# R7FA6M4AF register map
Vendor: Renesas Electronics Corporation; Series: RA6; File version: 1.30.00
CPU: CM33 r0p4, little endian, MPU, FPU, VTOR, 4 interrupt priority bits, 96 interrupts
Registers are 8-bit, read-write, reset 0x0 unless marked. A register's access mark holds for its fields unless they carry their own. Offsets are from the block's base; [hi:lo] are bit positions.

## ETHERC0 — Ethernet Controller Channel 0
Base 0x40114100
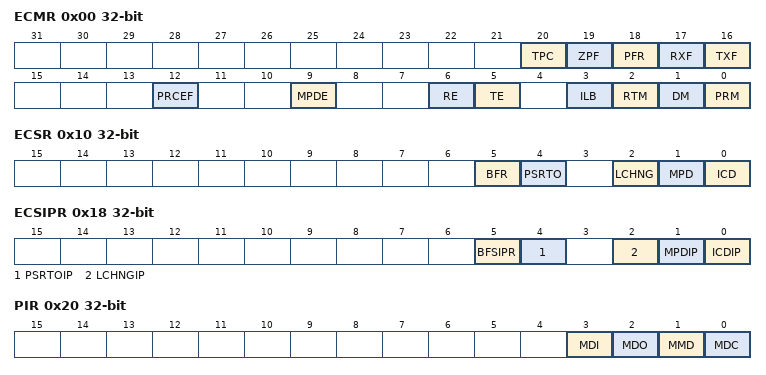
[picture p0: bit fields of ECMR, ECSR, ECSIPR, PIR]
0x00 ECMR 32-bit — ETHERC Mode Register
  [20] TPC — PAUSE Frame Transmit
  [19] ZPF — 0 Time PAUSE Frame Enable
  [18] PFR — PAUSE Frame Receive Mode
  [17] RXF — Receive Flow Control Operating Mode
  [16] TXF — Transmit Flow Control Operating Mode
  [12] PRCEF — CRC Error Frame Receive Mode
  [9] MPDE — Magic Packet Detection Enable
  [6] RE — Reception Enable
  [5] TE — Transmission Enable
  [3] ILB — Internal Loopback Mode
  [2] RTM — Bit Rate
  [1] DM — Duplex Mode
  [0] PRM — Promiscuous Mode
0x08 RFLR 32-bit — Receive Frame Maximum Length Register
  [11:0] RFL — Receive Frame Maximum Length
0x10 ECSR 32-bit — ETHERC Status Register
  [5] BFR — Continuous Broadcast Frame Reception Flag
  [4] PSRTO — PAUSE Frame Retransmit Over Flag
  [2] LCHNG — Link Signal Change Flag
  [1] MPD — Magic Packet Detect Flag
  [0] ICD — False Carrier Detect Flag
0x18 ECSIPR 32-bit — ETHERC Interrupt Enable Register
  [5] BFSIPR — Continuous Broadcast Frame Reception Interrupt Enable
  [4] PSRTOIP — PAUSE Frame Retransmit Over Interrupt Enable
  [2] LCHNGIP — LINK Signal Change Interrupt Enable
  [1] MPDIP — Magic Packet Detect Interrupt Enable
  [0] ICDIP — False Carrier Detect Interrupt Enable
0x20 PIR 32-bit (reset mask 0xFFFFFFF7) — PHY Interface Register
  [3] MDI ro — MII/RMII Management Data,In
  [2] MDO — MII/RMII Management Data,Out
  [1] MMD — MII/RMII Management Mode
  [0] MDC — MII/RMII Management Data Clock
0x28 PSR 32-bit ro (reset mask 0xFFFFFFFE) — PHY Status Register
  [0] LMON — ET0_LINKSTA Pin Status Flag
0x40 RDMLR 32-bit (reset mask 0xFFFF0000) — Random Number Generation Counter Upper Limit Setting Register
  [19:0] RMD — Random Number Generation Counter
0x50 IPGR 32-bit reset 0x14 — Interpacket Gap Register
  [4:0] IPG
0x54 APR 32-bit — Automatic PAUSE Frame Register
  [15:0] AP — Automatic PAUSE Time Setting
0x58 MPR 32-bit (reset mask 0xFFFF0000) — Manual PAUSE Frame Register
  [15:0] MP — Manual PAUSE Time Setting
0x60 RFCF 32-bit ro — Received PAUSE Frame Counter
  [7:0] RPAUSE — Received PAUSE Frame Count
0x64 TPAUSER 32-bit — PAUSE Frame Retransmit Count Setting Register
  [15:0] TPAUSE
0x68 TPAUSECR 32-bit ro — PAUSE Frame Retransmit Counter
  [7:0] TXP — PAUSE Frame Retransmit Count
0x6C BCFRR 32-bit — Broadcast Frame Receive Count Setting Register
  [15:0] BCF
0xC0 MAHR 32-bit — MAC Address Upper Bit Register
  [31:0] MAHR — MAC Address Upper Bit
0xC8 MALR 32-bit — MAC Address Lower Bit Register
  [15:0] MALR — MAC Address Lower Bit
0xD0 TROCR 32-bit — Transmit Retry Over Counter Register
  [31:0] TROCR — Transmit Retry Over Counter
0xD4 CDCR 32-bit — Late Collision Detect Counter Register
  [31:0] CDCR — Late Collision Detect Counter
0xD8 LCCR 32-bit — Lost Carrier Counter Register
  [31:0] LCCR — Lost Carrier Counter
0xDC CNDCR 32-bit — Carrier Not Detect Counter Register
  [31:0] CNDCR — Carrier Not Detect Counter
0xE4 CEFCR 32-bit — CRC Error Frame Receive Counter Register
  [31:0] CEFCR — CRC Error Frame Receive Counter
0xE8 FRECR 32-bit — Frame Receive Error Counter Register
  [31:0] FRECR — Frame Receive Error Counter
0xEC TSFRCR 32-bit — Too,Short Frame Receive Counter Register
  [31:0] TSFRCR — Too,Short Frame Receive Counter
0xF0 TLFRCR 32-bit — Too,Long Frame Receive Counter Register
  [31:0] TLFRCR — Too,Long Frame Receive Counter
0xF4 RFCR 32-bit — Received Alignment Error Frame Counter Register
  [31:0] RFCR — Received Alignment Error Frame Counter
0xF8 MAFCR 32-bit — Multicast Address Frame Receive Counter Register
  [31:0] MAFCR — Multicast Address Frame Receive Counter
